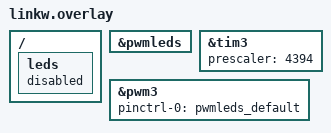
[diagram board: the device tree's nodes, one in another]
/*
 * Copyright (c) 2025 Michael Hope <michaelh@juju.nz>
 *
 * SPDX-License-Identifier: Apache-2.0
 */

/ {
	leds {
		status = "disabled";
	};
};

&pwmleds {
	status = "okay";
};

&tim3 {
	status = "okay";
	/*
	 * The sample blinks the LED at 0.5 Hz, ceil(144 MHz / 65536 / 0.5 Hz)
	 * is 4395, and the prescaler property is one less than that.
	 */
	prescaler = <4394>;
};

&pwm3 {
	status = "okay";
	pinctrl-0 = <&pwmleds_default>;
	pinctrl-names = "default";
};
